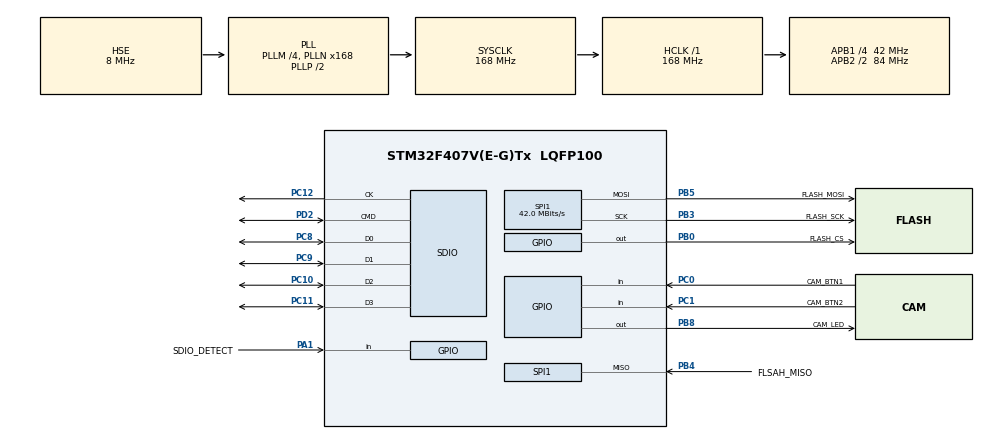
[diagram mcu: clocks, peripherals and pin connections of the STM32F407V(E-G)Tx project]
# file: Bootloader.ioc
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FATFS.BSP.number=1
FATFS._MAX_SS=4096
FATFS._USE_LFN=1
FATFS0.BSP.STBoard=false
FATFS0.BSP.api=Unknown
FATFS0.BSP.instance=PA1
FATFS0.BSP.ip=GPIO
FATFS0.BSP.mode=Input
FATFS0.BSP.name=Detect_SDIO
FATFS0.BSP.solution=PA1
Mcu.Family=STM32F4
Mcu.Name=STM32F407V(E-G)Tx
Mcu.Package=LQFP100
NVIC.PriorityGroup=NVIC_PRIORITYGROUP_4
PA1.GPIO_Label=SDIO_DETECT
PA1.GPIO_PuPd=GPIO_PULLDOWN
PA1.Signal=GPIO_Input
PA13.Mode=Serial_Wire
PA13.Signal=SYS_JTMS-SWDIO
PA14.Mode=Serial_Wire
PA14.Signal=SYS_JTCK-SWCLK
PB0.GPIO_Label=FLASH_CS
PB0.GPIO_Speed=GPIO_SPEED_FREQ_VERY_HIGH
PB0.PinState=GPIO_PIN_SET
PB0.Signal=GPIO_Output
PB3.GPIO_Label=FLASH_SCK
PB3.Mode=Full_Duplex_Master
PB3.Signal=SPI1_SCK
PB4.GPIO_Label=FLSAH_MISO
PB4.Mode=Full_Duplex_Master
PB4.Signal=SPI1_MISO
PB5.GPIO_Label=FLASH_MOSI
PB5.Mode=Full_Duplex_Master
PB5.Signal=SPI1_MOSI
PB8.GPIO_Label=CAM_LED
PB8.Signal=GPIO_Output
PC0.GPIO_Label=CAM_BTN1
PC0.Signal=GPIO_Input
PC1.GPIO_Label=CAM_BTN2
PC1.Signal=GPIO_Input
PC10.GPIO_PuPd=GPIO_PULLUP
PC10.Mode=SD_4_bits_Wide_bus
PC10.Signal=SDIO_D2
PC11.GPIO_PuPd=GPIO_PULLUP
PC11.Mode=SD_4_bits_Wide_bus
PC11.Signal=SDIO_D3
PC12.GPIO_PuPd=GPIO_PULLUP
PC12.Mode=SD_4_bits_Wide_bus
PC12.Signal=SDIO_CK
PC8.GPIO_PuPd=GPIO_PULLUP
PC8.Mode=SD_4_bits_Wide_bus
PC8.Signal=SDIO_D0
PC9.GPIO_PuPd=GPIO_PULLUP
PC9.Mode=SD_4_bits_Wide_bus
PC9.Signal=SDIO_D1
PD2.GPIO_PuPd=GPIO_PULLUP
PD2.Mode=SD_4_bits_Wide_bus
PD2.Signal=SDIO_CMD
PH0-OSC_IN.Mode=HSE-External-Oscillator
PH0-OSC_IN.Signal=RCC_OSC_IN
PH1-OSC_OUT.Mode=HSE-External-Oscillator
PH1-OSC_OUT.Signal=RCC_OSC_OUT
ProjectManager.HeapSize=0x200
ProjectManager.StackSize=0x400
ProjectManager.TargetToolchain=STM32CubeIDE
RCC.48MHZClocksFreq_Value=48000000
RCC.AHBFreq_Value=168000000
RCC.APB1CLKDivider=RCC_HCLK_DIV4
RCC.APB1Freq_Value=42000000
RCC.APB1TimFreq_Value=84000000
RCC.APB2CLKDivider=RCC_HCLK_DIV2
RCC.APB2Freq_Value=84000000
RCC.APB2TimFreq_Value=168000000
RCC.CortexFreq_Value=168000000
RCC.HCLKFreq_Value=168000000
RCC.HSE_VALUE=8000000
RCC.HSI_VALUE=16000000
RCC.LSE_VALUE=32768
RCC.PLLM=4
RCC.PLLN=168
RCC.PLLQ=7
RCC.PLLSourceVirtual=RCC_PLLSOURCE_HSE
RCC.SYSCLKFreq_VALUE=168000000
RCC.SYSCLKSource=RCC_SYSCLKSOURCE_PLLCLK
RCC.VCOOutputFreq_Value=336000000
SDIO.ClockDiv=4
SPI1.CalculateBaudRate=42.0 MBits/s
SPI1.Direction=SPI_DIRECTION_2LINES
SPI1.Mode=SPI_MODE_MASTER
SPI1.VirtualType=VM_MASTER
VP_CRC_VS_CRC.Mode=CRC_Activate
VP_FATFS_VS_SDIO.Mode=SDIO
board=custom

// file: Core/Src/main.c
/* USER CODE BEGIN Header */
/**
  ******************************************************************************
  * @file           : main.c
  * @brief          : Main program body
  ******************************************************************************
  * @attention
  *
  * Copyright (c) 2024 STMicroelectronics.
  * All rights reserved.
  *
  * This software is licensed under terms that can be found in the LICENSE file
  * in the root directory of this software component.
  * If no LICENSE file comes with this software, it is provided AS-IS.
  *
  ******************************************************************************
  */
/* USER CODE END Header */
#include "main.h"
#include "crc.h"
#include "fatfs.h"
#include "sdio.h"
#include "spi.h"
#include "gpio.h"

/* USER CODE BEGIN Includes */
#include "Bootloader.h"
/* USER CODE END Includes */

/* USER CODE BEGIN PM */

#define BL_COMBINED_VERSION      ((BL_MAJOR_VERSION << 16) | (BL_MINOR_VERSION))
/* USER CODE END PM */

/* USER CODE BEGIN PV */

/* SW Metadata: CRC and Version */
__attribute__((section(".bl_metadata")))\
const Metadata_t bl_metadata =
{
    .crc_value = 0xFFFFFFFF,         // CRC32 (to be updated by the script)
    .version = BL_COMBINED_VERSION,  // Combined major and minor version
};

/* Application HEADER */
__attribute__((section(".bl_header")))\
const Header_t bl_header = {
    .metadata_addr = (uint32_t)&bl_metadata,
    .label = BOOTLOADER_SW,
};
/* USER CODE END PV */

void SystemClock_Config(void);

int main(void)
{

  /* MCU Configuration--------------------------------------------------------*/

  /* Reset of all peripherals, Initializes the Flash interface and the Systick. */
  HAL_Init();

  /* Configure the system clock */
  SystemClock_Config();

  /* Initialize all configured peripherals */
  MX_GPIO_Init();
  MX_CRC_Init();
  MX_SDIO_SD_Init();
  MX_FATFS_Init();
  MX_SPI1_Init();
  /* USER CODE BEGIN 2 */

  /* Bootloader Main Function (endless) */
  BL_Main();

  /* USER CODE END 2 */

  /* Infinite loop */
  while (1)
  {

  }
}

void SystemClock_Config(void)
{
  RCC_OscInitTypeDef RCC_OscInitStruct = {0};
  RCC_ClkInitTypeDef RCC_ClkInitStruct = {0};

  /** Configure the main internal regulator output voltage
  */
  __HAL_RCC_PWR_CLK_ENABLE();
  __HAL_PWR_VOLTAGESCALING_CONFIG(PWR_REGULATOR_VOLTAGE_SCALE1);

  /** Initializes the RCC Oscillators according to the specified parameters
  * in the RCC_OscInitTypeDef structure.
  */
  RCC_OscInitStruct.OscillatorType = RCC_OSCILLATORTYPE_HSE;
  RCC_OscInitStruct.HSEState = RCC_HSE_ON;
  RCC_OscInitStruct.PLL.PLLState = RCC_PLL_ON;
  RCC_OscInitStruct.PLL.PLLSource = RCC_PLLSOURCE_HSE;
  RCC_OscInitStruct.PLL.PLLM = 4;
  RCC_OscInitStruct.PLL.PLLN = 168;
  RCC_OscInitStruct.PLL.PLLP = RCC_PLLP_DIV2;
  RCC_OscInitStruct.PLL.PLLQ = 7;
  if (HAL_RCC_OscConfig(&RCC_OscInitStruct) != HAL_OK)
  {
    Error_Handler();
  }

  /** Initializes the CPU, AHB and APB buses clocks
  */
  RCC_ClkInitStruct.ClockType = RCC_CLOCKTYPE_HCLK|RCC_CLOCKTYPE_SYSCLK
                              |RCC_CLOCKTYPE_PCLK1|RCC_CLOCKTYPE_PCLK2;
  RCC_ClkInitStruct.SYSCLKSource = RCC_SYSCLKSOURCE_PLLCLK;
  RCC_ClkInitStruct.AHBCLKDivider = RCC_SYSCLK_DIV1;
  RCC_ClkInitStruct.APB1CLKDivider = RCC_HCLK_DIV4;
  RCC_ClkInitStruct.APB2CLKDivider = RCC_HCLK_DIV2;

  if (HAL_RCC_ClockConfig(&RCC_ClkInitStruct, FLASH_LATENCY_5) != HAL_OK)
  {
    Error_Handler();
  }
}

void Error_Handler(void)
{
  __disable_irq();
  while (1)
  {
  }
}
